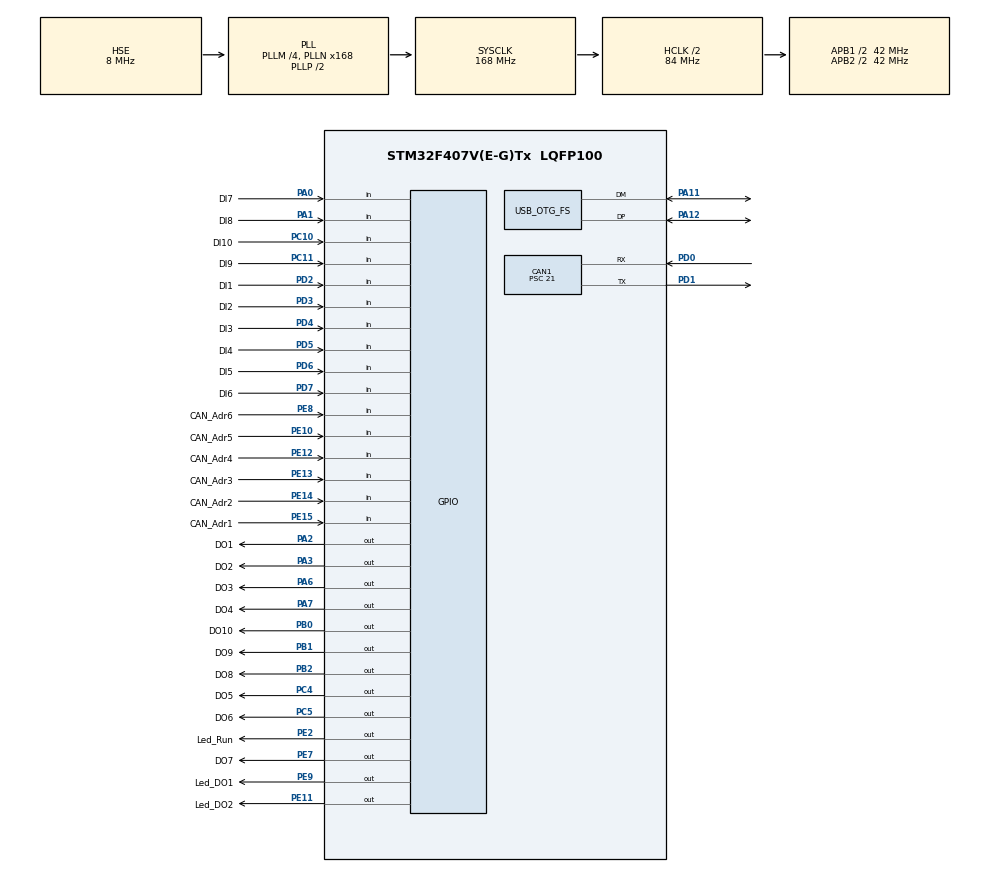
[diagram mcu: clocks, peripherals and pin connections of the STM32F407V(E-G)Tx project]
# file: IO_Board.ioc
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CAN1.BS1=CAN_BS1_13TQ
CAN1.BS2=CAN_BS2_2TQ
CAN1.CalculateBaudRate=125000
CAN1.CalculateTimeBit=8000
CAN1.CalculateTimeQuantum=500.0
CAN1.Prescaler=21
Mcu.Family=STM32F4
Mcu.Name=STM32F407V(E-G)Tx
Mcu.Package=LQFP100
NVIC.CAN1_RX0_IRQn=true\:0\:0\:false\:false\:true\:true\:true\:true
NVIC.CAN1_TX_IRQn=true\:0\:0\:false\:false\:true\:true\:true\:true
NVIC.PriorityGroup=NVIC_PRIORITYGROUP_4
NVIC.TIM1_UP_TIM10_IRQn=true\:15\:0\:false\:false\:true\:false\:true\:true
NVIC.TimeBase=TIM1_UP_TIM10_IRQn
NVIC.TimeBaseIP=TIM1
PA0-WKUP.GPIO_Label=DI7
PA0-WKUP.Signal=GPIO_Input
PA1.GPIO_Label=DI8
PA1.Signal=GPIO_Input
PA11.Mode=Device_Only
PA11.Signal=USB_OTG_FS_DM
PA12.Mode=Device_Only
PA12.Signal=USB_OTG_FS_DP
PA13.Mode=Serial_Wire
PA13.Signal=SYS_JTMS-SWDIO
PA14.Mode=Serial_Wire
PA14.Signal=SYS_JTCK-SWCLK
PA2.GPIO_Label=DO1
PA2.Signal=GPIO_Output
PA3.GPIO_Label=DO2
PA3.Signal=GPIO_Output
PA6.GPIO_Label=DO3
PA6.Signal=GPIO_Output
PA7.GPIO_Label=DO4
PA7.Signal=GPIO_Output
PB0.GPIO_Label=DO10
PB0.Signal=GPIO_Output
PB1.GPIO_Label=DO9
PB1.Signal=GPIO_Output
PB2.GPIO_Label=DO8
PB2.Signal=GPIO_Output
PC10.GPIO_Label=DI10
PC10.Signal=GPIO_Input
PC11.GPIO_Label=DI9
PC11.Signal=GPIO_Input
PC4.GPIO_Label=DO5
PC4.Signal=GPIO_Output
PC5.GPIO_Label=DO6
PC5.Signal=GPIO_Output
PD0.Mode=CAN_Activate
PD0.Signal=CAN1_RX
PD1.Mode=CAN_Activate
PD1.Signal=CAN1_TX
PD2.GPIO_Label=DI1
PD2.Signal=GPIO_Input
PD3.GPIO_Label=DI2
PD3.Signal=GPIO_Input
PD4.GPIO_Label=DI3
PD4.Signal=GPIO_Input
PD5.GPIO_Label=DI4
PD5.Signal=GPIO_Input
PD6.GPIO_Label=DI5
PD6.Signal=GPIO_Input
PD7.GPIO_Label=DI6
PD7.Signal=GPIO_Input
PE10.GPIO_Label=CAN_Adr5
PE10.Signal=GPIO_Input
PE11.GPIO_Label=Led_DO2
PE11.Signal=GPIO_Output
PE12.GPIO_Label=CAN_Adr4
PE12.Signal=GPIO_Input
PE13.GPIO_Label=CAN_Adr3
PE13.Signal=GPIO_Input
PE14.GPIO_Label=CAN_Adr2
PE14.Signal=GPIO_Input
PE15.GPIO_Label=CAN_Adr1
PE15.Signal=GPIO_Input
PE2.GPIO_Label=Led_Run
PE2.Signal=GPIO_Output
PE7.GPIO_Label=DO7
PE7.Signal=GPIO_Output
PE8.GPIO_Label=CAN_Adr6
PE8.Signal=GPIO_Input
PE9.GPIO_Label=Led_DO1
PE9.Signal=GPIO_Output
PH0-OSC_IN.Mode=HSE-External-Oscillator
PH0-OSC_IN.Signal=RCC_OSC_IN
PH1-OSC_OUT.Mode=HSE-External-Oscillator
PH1-OSC_OUT.Signal=RCC_OSC_OUT
ProjectManager.HeapSize=0x200
ProjectManager.StackSize=0x400
ProjectManager.TargetToolchain=CMake
RCC.48MHZClocksFreq_Value=48000000
RCC.AHBCLKDivider=RCC_SYSCLK_DIV2
RCC.AHBFreq_Value=84000000
RCC.APB1CLKDivider=RCC_HCLK_DIV2
RCC.APB1Freq_Value=42000000
RCC.APB1TimFreq_Value=84000000
RCC.APB2CLKDivider=RCC_HCLK_DIV2
RCC.APB2Freq_Value=42000000
RCC.APB2TimFreq_Value=84000000
RCC.CortexFreq_Value=84000000
RCC.HCLKFreq_Value=84000000
RCC.HSE_VALUE=8000000
RCC.HSI_VALUE=16000000
RCC.LSE_VALUE=32768
RCC.PLLM=4
RCC.PLLN=168
RCC.PLLQ=7
RCC.SYSCLKFreq_VALUE=168000000
RCC.SYSCLKSource=RCC_SYSCLKSOURCE_PLLCLK
RCC.VCOOutputFreq_Value=336000000
USB_OTG_FS.VirtualMode=Device_Only
VP_SYS_VS_tim1.Mode=TIM1
board=custom

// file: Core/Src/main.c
/* USER CODE BEGIN Header */
/**
  ******************************************************************************
  * @file           : main.c
  * @brief          : Main program body
  ******************************************************************************
  * @attention
  *
  * Copyright (c) 2026 STMicroelectronics.
  * All rights reserved.
  *
  * This software is licensed under terms that can be found in the LICENSE file
  * in the root directory of this software component.
  * If no LICENSE file comes with this software, it is provided AS-IS.
  *
  ******************************************************************************
  */
/* USER CODE END Header */
#include "main.h"
#include "can.h"
#include "usb_otg.h"
#include "gpio.h"

/* USER CODE BEGIN Includes */
#include "Machine.h"
#include "Timer.h"

/* USER CODE END Includes */

void SystemClock_Config(void);

int main(void)
{

  /* MCU Configuration--------------------------------------------------------*/

  /* Reset of all peripherals, Initializes the Flash interface and the Systick. */
  HAL_Init();

  /* Configure the system clock */
  SystemClock_Config();

  /* Initialize all configured peripherals */
  MX_GPIO_Init();
  MX_CAN1_Init();
  MX_USB_OTG_FS_PCD_Init();
  /* USER CODE BEGIN 2 */
  Machine_init();

  /* USER CODE END 2 */

  /* Infinite loop */
  while (1)
  {

    /* USER CODE BEGIN 3 */
    Machine_loop();
  }
  /* USER CODE END 3 */
}

void SystemClock_Config(void)
{
  RCC_OscInitTypeDef RCC_OscInitStruct = {0};
  RCC_ClkInitTypeDef RCC_ClkInitStruct = {0};

  /** Configure the main internal regulator output voltage
  */
  __HAL_RCC_PWR_CLK_ENABLE();
  __HAL_PWR_VOLTAGESCALING_CONFIG(PWR_REGULATOR_VOLTAGE_SCALE1);

  /** Initializes the RCC Oscillators according to the specified parameters
  * in the RCC_OscInitTypeDef structure.
  */
  RCC_OscInitStruct.OscillatorType = RCC_OSCILLATORTYPE_HSE;
  RCC_OscInitStruct.HSEState = RCC_HSE_ON;
  RCC_OscInitStruct.PLL.PLLState = RCC_PLL_ON;
  RCC_OscInitStruct.PLL.PLLSource = RCC_PLLSOURCE_HSE;
  RCC_OscInitStruct.PLL.PLLM = 4;
  RCC_OscInitStruct.PLL.PLLN = 168;
  RCC_OscInitStruct.PLL.PLLP = RCC_PLLP_DIV2;
  RCC_OscInitStruct.PLL.PLLQ = 7;
  if (HAL_RCC_OscConfig(&RCC_OscInitStruct) != HAL_OK)
  {
    Error_Handler();
  }

  /** Initializes the CPU, AHB and APB buses clocks
  */
  RCC_ClkInitStruct.ClockType = RCC_CLOCKTYPE_HCLK|RCC_CLOCKTYPE_SYSCLK
                              |RCC_CLOCKTYPE_PCLK1|RCC_CLOCKTYPE_PCLK2;
  RCC_ClkInitStruct.SYSCLKSource = RCC_SYSCLKSOURCE_PLLCLK;
  RCC_ClkInitStruct.AHBCLKDivider = RCC_SYSCLK_DIV2;
  RCC_ClkInitStruct.APB1CLKDivider = RCC_HCLK_DIV2;
  RCC_ClkInitStruct.APB2CLKDivider = RCC_HCLK_DIV2;

  if (HAL_RCC_ClockConfig(&RCC_ClkInitStruct, FLASH_LATENCY_2) != HAL_OK)
  {
    Error_Handler();
  }
}

void HAL_TIM_PeriodElapsedCallback(TIM_HandleTypeDef *htim)
{
  if (htim->Instance == TIM1)
  {
    HAL_IncTick();
  }
  /* USER CODE BEGIN Callback 1 */
  if (htim->Instance == TIM1)
  {
    scanTimer();
  }

  /* USER CODE END Callback 1 */
}

void Error_Handler(void)
{
  __disable_irq();
  while (1)
  {
  }
}
